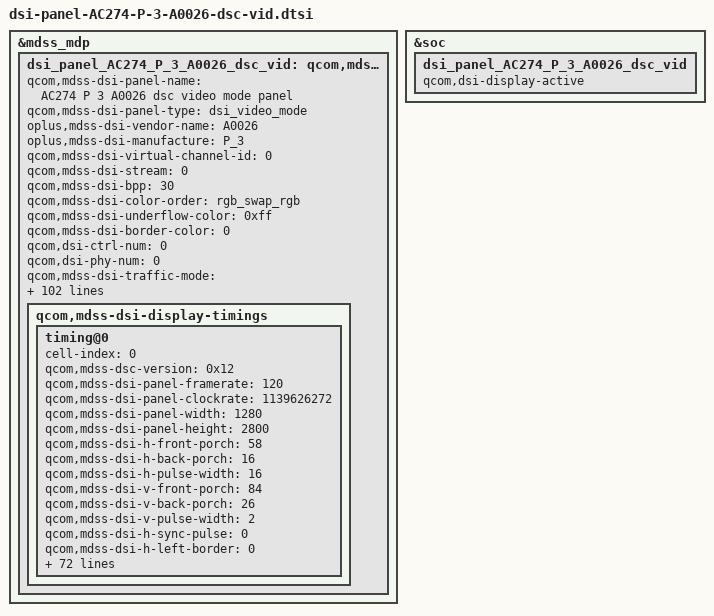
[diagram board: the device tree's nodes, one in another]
&mdss_mdp {
	dsi_panel_AC274_P_3_A0026_dsc_vid: qcom,mdss_dsi_panel_AC274_P_3_A0026_dsc_vid {
		qcom,mdss-dsi-panel-name = "AC274 P 3 A0026 dsc video mode panel";
		qcom,mdss-dsi-panel-type = "dsi_video_mode";
		oplus,mdss-dsi-vendor-name = "A0026";
		oplus,mdss-dsi-manufacture = "P_3";
		qcom,mdss-dsi-virtual-channel-id = <0>;
		qcom,mdss-dsi-stream = <0>;
		qcom,mdss-dsi-bpp = <30>;
		qcom,mdss-dsi-color-order = "rgb_swap_rgb";
		qcom,mdss-dsi-underflow-color = <0xff>;
		qcom,mdss-dsi-border-color = <0>;
		qcom,dsi-ctrl-num = <0>;
		qcom,dsi-phy-num = <0>;
		qcom,mdss-dsi-traffic-mode = "non_burst_sync_pulse";
		qcom,mdss-dsi-lane-map = "lane_map_0123";
		qcom,mdss-dsi-bllp-eof-power-mode;
		qcom,mdss-dsi-bllp-power-mode;
		qcom,mdss-dsi-lane-0-state;
		qcom,mdss-dsi-lane-1-state;
		qcom,mdss-dsi-lane-2-state;
		qcom,mdss-dsi-lane-3-state;
		qcom,mdss-dsi-dma-trigger = "trigger_sw";
		qcom,mdss-dsi-mdp-trigger = "none";
		qcom,mdss-dsi-reset-sequence = <1 10>, <0 10>, <1 25>;
		qcom,mdss-pan-physical-width-dimension = <72>;
		qcom,mdss-pan-physical-height-dimension = <157>;
		qcom,mdss-dsi-init-delay-us = <1000>;
		qcom,mdss-dsi-panel-jitter = <0x4 0x1>;
		/* disable cesta */
		qcom,mdss-disable-cesta-hw-sleep;
		//qcom,mdss-dsi-dma-schedule-line = <5>;
		qcom,mdss-dsi-dma-schedule-line-60 = <2600>;
		qcom,mdss-dsi-dma-schedule-line-90 = <600>;
		qcom,mdss-dsi-dma-schedule-line-120 = <30>;
		//qcom,mdss-bl-high2bit;
		//qcom,mdss-disable-cesta-hw-sleep;
		//qcom,mdss-dsi-panel-peak-brightness = <5400000>;
		/* HDR Setting */
		//update for [MPC15]PerformanceClassTest#testDisplayHdr pass
		qcom,mdss-dsi-panel-hdr-enabled;
		qcom,mdss-dsi-panel-hdr-color-primaries = <15635 16450 34000 16000 13250 34500 7500 3000>;
		qcom,mdss-dsi-panel-peak-brightness = <20000000>;
		qcom,mdss-dsi-panel-average-brightness = <2000000>;
		qcom,mdss-dsi-panel-blackness-level = <4000>;
		/*color*/
		oplus,color_vivid_status;
		//oplus,color_srgb_status;
		//oplus,color_softiris_status;
		//oplus,color_oplus_calibrate_status;
		//oplus,color_dual_brightness_status;
		//oplus,color_2nit_status;
		//oplus,color_loading_status;
		//oplus,color_nature_profession_status;
		//oplus,mdss-dsi-panel-type = <0>;
		//qcom,dynamic-mode-switch-enabled;
		qcom,dynamic-mode-switch-type = "dynamic-resolution-switch-immediate";
		qcom,mdss-dsi-display-timings {
			timing@0 {
				#include "dsi-panel-AC274-P-3-A0026-common-effect.dtsi"
				cell-index = <0>;
				//qcom,mdss-mdp-transfer-time-us = <6290>;
				//qcom,mdss-dsi-panel-jitter = <0x4 0x1>;
				qcom,mdss-dsc-version = <0x12>;
				//qcom,mdss-dsi-timing-default;
				qcom,mdss-dsi-panel-framerate = <120>;
				qcom,mdss-dsi-panel-clockrate = <1139626272>;
				qcom,mdss-dsi-panel-width = <1280>;
				qcom,mdss-dsi-panel-height = <2800>;

				qcom,mdss-dsi-h-front-porch = <58>;
				qcom,mdss-dsi-h-back-porch = <16>;
				qcom,mdss-dsi-h-pulse-width = <16>;
				qcom,mdss-dsi-v-front-porch = <84>;
				qcom,mdss-dsi-v-back-porch = <26>;
				qcom,mdss-dsi-v-pulse-width = <2>;
				qcom,mdss-dsi-h-sync-pulse = <0>;
				qcom,mdss-dsi-h-left-border = <0>;
				qcom,mdss-dsi-h-right-border = <0>;
				qcom,mdss-dsi-v-top-border = <0>;
				qcom,mdss-dsi-v-bottom-border = <0>;

				//oplus,ofp-need-to-sync-data-in-aod-unlocking;
				//oplus,ofp-aod-off-insert-black-frame = <1>;
				//oplus,ofp-aod-off-black-frame-total-time = <42>;
				//oplus,ofp-need-to-separate-backlight;
				//oplus,ofp-backlight-on-period = <1>;

				/* panel C1 PVT */
				qcom,mdss-dsi-on-command = [
					/* OSC2 = 138.9Mhz */
					39 00 00 40 00 00 06 F0 55 AA 52 08 01
					15 00 00 40 00 00 02 6F 03
					15 00 00 40 00 00 02 C4 62
					/* VGXP by pad cap */
					39 00 00 40 00 00 05 FF AA 55 A5 80
					15 00 00 40 00 00 02 6F 1F
					15 00 00 40 00 00 02 F4 0F
					15 00 00 40 00 00 02 6F 20
					39 00 00 40 00 00 02 F4 0F
					15 00 00 40 00 00 02 6F 08
					15 00 00 40 00 00 02 FC 01
					39 00 00 40 00 00 05 FF AA 55 A5 80
					15 00 00 40 00 00 02 6F 24
					15 00 00 40 00 00 02 F8 FF
					/* esd enhance*/
					39 00 00 40 00 00 06 F0 55 AA 52 08 00
					15 00 00 40 00 00 02 6F 0F
					15 00 00 40 00 00 02 D8 42
					39 00 00 40 00 00 06 F0 55 AA 52 08 00
					15 00 00 40 00 00 02 6F D4
					15 00 00 40 00 00 02 BA 20
					39 00 00 40 00 00 06 F0 55 AA 52 08 03
					15 00 00 40 00 00 02 C6 87
					/* For idle enter BIST */
					39 00 00 40 00 00 06 F0 55 AA 52 08 00
					15 00 00 40 00 00 02 C0 00
					39 00 00 40 00 00 06 F0 55 AA 52 08 01
					15 00 00 40 00 00 02 6F 0B
					39 00 00 40 00 00 02 D2 00
					39 00 00 40 00 00 05 FF AA 55 A5 84
					15 00 00 40 00 00 02 6F 10
					39 00 00 40 00 00 02 F8 02
					39 00 00 40 00 00 05 FF AA 55 A5 84
					15 00 00 40 00 00 02 F2 15
					/* LCTC Constraint for esd improve*/
					39 00 00 40 00 00 05 FF AA 55 A5 84
					15 00 00 40 00 00 02 6F A9
					15 00 00 40 00 00 02 F4 F3
					/* Resolution Setting */
					39 00 00 40 00 00 05 2A 00 00 04 FF
					39 00 00 40 00 00 05 2B 00 00 0A EF
					/* Vesa1.2 10bit 3.75 Dsc Setting */
					15 00 00 40 00 00 02 90 03
					15 00 00 40 00 00 02 6F 01
					39 00 00 40 00 00 02 90 43
					39 00 00 40 00 00 13 91 AB A8 00 28 D2 00 02 5C 04 06 00 08 02 AB 02 20 10 E0
					/* Dimming Off */
					15 00 00 40 00 00 02 53 20
					/* video mode ext_vfp,vbp setting */
					39 00 00 40 00 00 11 3B 00 1C 00 58 00 1C 00 54 00 1C 04 0C 00 1C 0B B4
					15 00 00 40 00 00 02 6F 10
					39 00 00 40 00 00 05 3B 00 1C 00 54
					/* DPC Temperature Setting */
					39 00 00 40 00 00 03 81 01 19
					/* FPR1 EN */
					15 00 00 40 00 00 02 88 01
					/* 120Hz sleep out */
					39 00 00 40 00 00 07 A9 01 00 2F 00 00 01
					/* TE on */
					15 00 00 40 00 00 02 35 00
					/* Setting loading effect x1.0 */
					39 00 00 40 00 00 03 5F 00 00
					/* Optimize the slight blue smear in low brightness */
					39 00 00 40 00 00 06 F0 55 AA 52 08 08
					39 00 00 40 00 00 05 E0 41 01 01 01
					15 00 00 40 00 00 02 6F 1C
					39 00 00 40 00 00 05 E1 01 07 0D 05
					15 00 00 40 00 00 02 6F 2A
					39 00 00 40 00 00 05 E1 01 0B 0D 04
					15 00 00 40 00 00 02 6F 38
					39 00 00 40 00 00 05 E1 02 0B 0A 08
					15 00 00 40 00 00 02 6F 46
					39 00 00 40 00 00 05 E1 02 09 08 05
					15 00 00 40 00 00 02 6F 54
					39 00 00 40 00 00 05 E1 01 07 09 04

					15 00 00 40 00 00 02 6F 1C
					39 00 00 40 00 00 05 E2 01 09 0D 05
					15 00 00 40 00 00 02 6F 2A
					39 00 00 40 00 00 05 E2 02 0D 0E 06
					15 00 00 40 00 00 02 6F 38
					39 00 00 40 00 00 05 E2 02 09 0A 07
					15 00 00 40 00 00 02 6F 46
					39 00 00 40 00 00 05 E2 02 09 09 07
					15 00 00 40 00 00 02 6F 54
					39 00 00 40 00 00 05 E2 02 07 0B 02
					/* swire pulse */
					39 00 00 40 00 00 06 F0 55 AA 52 08 00
					15 00 00 40 00 00 02 6F 03
					15 00 00 00 00 00 02 B5 D5
					/* Sleep out */
					/* FOD Coordinate location */
					39 00 00 40 00 00 06 F0 55 AA 52 08 00
					15 00 00 40 00 00 02 6F 07
					39 00 00 40 00 00 03 DF 02 1C
					15 00 00 40 00 00 02 6F 09
					39 00 00 40 00 00 03 DF 09 8C
					15 00 00 40 00 00 02 6F 0B
					39 00 00 40 00 00 03 DF 02 E6
					15 00 00 40 00 00 02 6F 0D
					39 00 00 40 00 00 03 DF 0A 56
					/* VDO Trim 139 */
					39 00 00 40 00 00 06 F0 55 AA 52 08 01
					15 00 00 40 00 00 02 6F 04
					15 00 00 40 00 00 02 C3 0A
					15 00 00 40 00 00 02 6F 09
					15 00 00 40 00 00 02 C3 0A

					15 00 00 40 00 00 02 EA C0
					15 00 00 40 00 00 02 6F 11
					15 00 00 40 00 00 02 EA C0
					15 00 00 40 00 00 02 6F 07
					39 00 00 40 00 00 06 EA 01 04 01 39 01
					15 00 00 40 00 00 02 6F 0C
					39 00 00 40 00 00 06 EA 3A 01 39 04 E2
					15 00 00 40 00 00 02 6F 18
					39 00 00 40 00 00 06 EA 01 4A 01 8E 01
					15 00 00 40 00 00 02 6F 1D
					39 00 00 40 00 00 06 EA 90 01 8E 06 37
					39 00 00 40 00 00 06 F0 55 AA 52 08 01
					15 00 00 40 00 00 02 6F 9B
					15 00 00 40 00 00 02 B9 80
					15 00 00 40 00 00 02 6F C3
					39 00 00 40 00 00 03 B9 01 80
					15 00 00 40 00 00 02 6F CB
					39 00 00 40 00 00 03 B9 01 80
					15 00 00 40 00 00 02 6F D3
					39 00 00 40 00 00 03 B9 01 80
					39 00 00 40 00 00 06 F0 55 AA 52 08 00
					39 00 00 40 00 00 05 FF AA 55 A5 80
					15 00 00 40 00 00 02 6F 47
					15 00 00 40 00 00 02 F2 21
					15 00 00 00 78 00 02 11 00
					15 00 00 00 14 00 02 29 00
					/*lhbm brightness -W255 Demora Gain -> 0*/
					39 00 00 40 00 00 06 F0 55 AA 52 08 04
					15 00 00 00 00 00 02 CB 06
				];

				/* panel C3 & T0 */
				qcom,mdss-dsi-optimize-on-command = [
					/* OSC2 = 138.9Mhz */
					39 00 00 40 00 00 06 F0 55 AA 52 08 01
					15 00 00 40 00 00 02 6F 03
					15 00 00 40 00 00 02 C4 62
					/* VGXP by pad cap */
					39 00 00 40 00 00 05 FF AA 55 A5 80
					15 00 00 40 00 00 02 6F 1F
					15 00 00 40 00 00 02 F4 0F
					15 00 00 40 00 00 02 6F 20
					39 00 00 40 00 00 02 F4 0F
					15 00 00 40 00 00 02 6F 08
					15 00 00 40 00 00 02 FC 01
					39 00 00 40 00 00 05 FF AA 55 A5 80
					15 00 00 40 00 00 02 6F 24
					15 00 00 40 00 00 02 F8 FF
					/* esd enhance*/
					39 00 00 40 00 00 06 F0 55 AA 52 08 00
					15 00 00 40 00 00 02 6F 0F
					15 00 00 40 00 00 02 D8 42
					39 00 00 40 00 00 06 F0 55 AA 52 08 00
					15 00 00 40 00 00 02 6F D4
					15 00 00 40 00 00 02 BA 20
					39 00 00 40 00 00 06 F0 55 AA 52 08 03
					15 00 00 40 00 00 02 C6 87
					/* For idle enter BIST */
					39 00 00 40 00 00 06 F0 55 AA 52 08 00
					15 00 00 40 00 00 02 C0 00
					39 00 00 40 00 00 06 F0 55 AA 52 08 01
					15 00 00 40 00 00 02 6F 0B
					39 00 00 40 00 00 02 D2 00
					39 00 00 40 00 00 05 FF AA 55 A5 84
					15 00 00 40 00 00 02 6F 10
					39 00 00 40 00 00 02 F8 02
					39 00 00 40 00 00 05 FF AA 55 A5 84
					15 00 00 40 00 00 02 F2 15
					/* LCTC Constraint For ESD Improve */
					39 00 00 40 00 00 05 FF AA 55 A5 84
					15 00 00 40 00 00 02 6F A9
					15 00 00 40 00 00 02 F4 F3
					/* CSC Setting */
					15 00 00 40 00 00 02 6F 14
					39 00 00 40 00 00 0A B0 F5 55 55 56 AA AA AA AA A8
					/* Resolution Setting */
					39 00 00 40 00 00 05 2A 00 00 04 FF
					39 00 00 40 00 00 05 2B 00 00 0A EF
					/* Vesa1.2 10bit 3.75 Dsc Setting */
					15 00 00 40 00 00 02 90 03
					15 00 00 40 00 00 02 6F 01
					39 00 00 40 00 00 02 90 43
					39 00 00 40 00 00 13 91 AB A8 00 28 D2 00 02 5C 04 06 00 08 02 AB 02 20 10 E0
					/* Dimming Off */
					15 00 00 40 00 00 02 53 20
					/* video mode ext_vfp,vbp setting */
					39 00 00 40 00 00 11 3B 00 1C 00 58 00 1C 00 54 00 1C 04 0C 00 1C 0B B4
					15 00 00 40 00 00 02 6F 10
					39 00 00 40 00 00 05 3B 00 1C 00 54
					/* DPC Temperature Setting */
					39 00 00 40 00 00 03 81 01 19
					/* FPR1 EN */
					15 00 00 40 00 00 02 88 01
					/* 120Hz sleep out */
					39 00 00 40 00 00 07 A9 01 00 2F 00 00 01
					/* TE on */
					15 00 00 40 00 00 02 35 00
					/* Setting loading effect x1.0 */
					39 00 00 40 00 00 03 5F 00 00
					/* Optimize the slight blue smear in low brightness */
					39 00 00 40 00 00 06 F0 55 AA 52 08 08
					39 00 00 40 00 00 05 E0 41 01 01 01
					15 00 00 40 00 00 02 6F 1C
					39 00 00 40 00 00 05 E1 01 07 0D 05
					15 00 00 40 00 00 02 6F 2A
					39 00 00 40 00 00 05 E1 01 0B 0D 04
					15 00 00 40 00 00 02 6F 38
					39 00 00 40 00 00 05 E1 02 0B 0A 08
					15 00 00 40 00 00 02 6F 46
					39 00 00 40 00 00 05 E1 02 09 08 05
					15 00 00 40 00 00 02 6F 54
					39 00 00 40 00 00 05 E1 01 07 09 04

					15 00 00 40 00 00 02 6F 1C
					39 00 00 40 00 00 05 E2 01 09 0D 05
					15 00 00 40 00 00 02 6F 2A
					39 00 00 40 00 00 05 E2 02 0D 0E 06
					15 00 00 40 00 00 02 6F 38
					39 00 00 40 00 00 05 E2 02 09 0A 07
					15 00 00 40 00 00 02 6F 46
					39 00 00 40 00 00 05 E2 02 09 09 07
					15 00 00 40 00 00 02 6F 54
					39 00 00 40 00 00 05 E2 02 07 0B 02
					/* swire pulse */
					39 00 00 40 00 00 06 F0 55 AA 52 08 00
					15 00 00 40 00 00 02 6F 03
					15 00 00 00 00 00 02 B5 D5
					/* Sleep out */
					/* FOD Coordinate location */
					39 00 00 40 00 00 06 F0 55 AA 52 08 00
					15 00 00 40 00 00 02 6F 07
					39 00 00 40 00 00 03 DF 02 1C
					15 00 00 40 00 00 02 6F 09
					39 00 00 40 00 00 03 DF 09 8C
					15 00 00 40 00 00 02 6F 0B
					39 00 00 40 00 00 03 DF 02 E6
					15 00 00 40 00 00 02 6F 0D
					39 00 00 40 00 00 03 DF 0A 56
					/* VDO Trim 139 */
					39 00 00 40 00 00 06 F0 55 AA 52 08 01
					15 00 00 40 00 00 02 6F 04
					15 00 00 40 00 00 02 C3 0A
					15 00 00 40 00 00 02 6F 09
					15 00 00 40 00 00 02 C3 0A

					15 00 00 40 00 00 02 EA C0
					15 00 00 40 00 00 02 6F 11
					15 00 00 40 00 00 02 EA C0
					15 00 00 40 00 00 02 6F 07
					39 00 00 40 00 00 06 EA 01 04 01 39 01
					15 00 00 40 00 00 02 6F 0C
					39 00 00 40 00 00 06 EA 3A 01 39 04 E2
					15 00 00 40 00 00 02 6F 18
					39 00 00 40 00 00 06 EA 01 4A 01 8E 01
					15 00 00 40 00 00 02 6F 1D
					39 00 00 40 00 00 06 EA 90 01 8E 06 37
					39 00 00 40 00 00 06 F0 55 AA 52 08 01
					15 00 00 40 00 00 02 6F 9B
					15 00 00 40 00 00 02 B9 80
					15 00 00 40 00 00 02 6F C3
					39 00 00 40 00 00 03 B9 01 80
					15 00 00 40 00 00 02 6F CB
					39 00 00 40 00 00 03 B9 01 80
					15 00 00 40 00 00 02 6F D3
					39 00 00 40 00 00 03 B9 01 80
					39 00 00 40 00 00 06 F0 55 AA 52 08 00
					39 00 00 40 00 00 05 FF AA 55 A5 80
					15 00 00 40 00 00 02 6F 47
					15 00 00 40 00 00 02 F2 21
					15 00 00 00 78 00 02 11 00
					15 00 00 00 14 00 02 29 00
					/*lhbm brightness -W255 Demora Gain -> 0*/
					39 00 00 40 00 00 06 F0 55 AA 52 08 04
					15 00 00 00 00 00 02 CB 06
				];

				/* panel C2 */
				qcom,mdss-dsi-optimize-vice-on-command = [
					/* OSC2 = 138.9Mhz */
					39 00 00 40 00 00 06 F0 55 AA 52 08 01
					15 00 00 40 00 00 02 6F 03
					15 00 00 40 00 00 02 C4 62
					/* VGXP by pad cap */
					39 00 00 40 00 00 05 FF AA 55 A5 80
					15 00 00 40 00 00 02 6F 1F
					15 00 00 40 00 00 02 F4 0F
					15 00 00 40 00 00 02 6F 20
					39 00 00 40 00 00 02 F4 0F
					15 00 00 40 00 00 02 6F 08
					15 00 00 40 00 00 02 FC 01
					39 00 00 40 00 00 05 FF AA 55 A5 80
					15 00 00 40 00 00 02 6F 24
					15 00 00 40 00 00 02 F8 FF
					/* esd enhance*/
					39 00 00 40 00 00 06 F0 55 AA 52 08 00
					15 00 00 40 00 00 02 6F 0F
					15 00 00 40 00 00 02 D8 42
					39 00 00 40 00 00 06 F0 55 AA 52 08 00
					15 00 00 40 00 00 02 6F D4
					15 00 00 40 00 00 02 BA 20
					39 00 00 40 00 00 06 F0 55 AA 52 08 03
					15 00 00 40 00 00 02 C6 87
					/* For idle enter BIST */
					39 00 00 40 00 00 06 F0 55 AA 52 08 00
					15 00 00 40 00 00 02 C0 00
					39 00 00 40 00 00 06 F0 55 AA 52 08 01
					15 00 00 40 00 00 02 6F 0B
					39 00 00 40 00 00 02 D2 00
					39 00 00 40 00 00 05 FF AA 55 A5 84
					15 00 00 40 00 00 02 6F 10
					39 00 00 40 00 00 02 F8 02
					39 00 00 40 00 00 05 FF AA 55 A5 84
					15 00 00 40 00 00 02 F2 15
					/* LCTC Constraint For ESD Improve */
					39 00 00 40 00 00 05 FF AA 55 A5 84
					15 00 00 40 00 00 02 6F A9
					15 00 00 40 00 00 02 F4 F3
					/* Resolution Setting */
					39 00 00 40 00 00 05 2A 00 00 04 FF
					39 00 00 40 00 00 05 2B 00 00 0A EF
					/* Vesa1.2 10bit 3.75 Dsc Setting */
					15 00 00 40 00 00 02 90 03
					15 00 00 40 00 00 02 6F 01
					39 00 00 40 00 00 02 90 43
					39 00 00 40 00 00 13 91 AB A8 00 28 D2 00 02 5C 04 06 00 08 02 AB 02 20 10 E0
					/* Dimming Off */
					15 00 00 40 00 00 02 53 20
					/* video mode ext_vfp,vbp setting */
					39 00 00 40 00 00 11 3B 00 1C 00 58 00 1C 00 54 00 1C 04 0C 00 1C 0B B4
					15 00 00 40 00 00 02 6F 10
					39 00 00 40 00 00 05 3B 00 1C 00 54
					/* DPC Temperature Setting */
					39 00 00 40 00 00 03 81 01 19
					/* FPR1 EN */
					15 00 00 40 00 00 02 88 01
					/* 120Hz sleep out */
					39 00 00 40 00 00 07 A9 01 00 2F 00 00 01
					/* TE on */
					15 00 00 40 00 00 02 35 00
					/* Setting loading effect x1.0 */
					39 00 00 40 00 00 03 5F 00 00
					/* Optimize the slight blue smear in low brightness */
					39 00 00 40 00 00 06 F0 55 AA 52 08 08
					39 00 00 40 00 00 05 E0 41 01 01 01
					15 00 00 40 00 00 02 6F 1C
					39 00 00 40 00 00 05 E1 01 07 0D 05
					15 00 00 40 00 00 02 6F 2A
					39 00 00 40 00 00 05 E1 01 0B 0D 04
					15 00 00 40 00 00 02 6F 38
					39 00 00 40 00 00 05 E1 02 0B 0A 08
					15 00 00 40 00 00 02 6F 46
					39 00 00 40 00 00 05 E1 02 09 08 05
					15 00 00 40 00 00 02 6F 54
					39 00 00 40 00 00 05 E1 01 07 09 04

					15 00 00 40 00 00 02 6F 1C
					39 00 00 40 00 00 05 E2 01 09 0D 05
					15 00 00 40 00 00 02 6F 2A
					39 00 00 40 00 00 05 E2 02 0D 0E 06
					15 00 00 40 00 00 02 6F 38
					39 00 00 40 00 00 05 E2 02 09 0A 07
					15 00 00 40 00 00 02 6F 46
					39 00 00 40 00 00 05 E2 02 09 09 07
					15 00 00 40 00 00 02 6F 54
					39 00 00 40 00 00 05 E2 02 07 0B 02
					/* swire pulse */
					39 00 00 40 00 00 06 F0 55 AA 52 08 00
					15 00 00 40 00 00 02 6F 03
					15 00 00 00 00 00 02 B5 D5
					/* Sleep out */
					/* FOD Coordinate location */
					39 00 00 40 00 00 06 F0 55 AA 52 08 00
					15 00 00 40 00 00 02 6F 07
					39 00 00 40 00 00 03 DF 02 1C
					15 00 00 40 00 00 02 6F 09
					39 00 00 40 00 00 03 DF 09 8C
					15 00 00 40 00 00 02 6F 0B
					39 00 00 40 00 00 03 DF 02 E6
					15 00 00 40 00 00 02 6F 0D
					39 00 00 40 00 00 03 DF 0A 56
					/* VDO Trim 139 */
					39 00 00 40 00 00 06 F0 55 AA 52 08 01
					15 00 00 40 00 00 02 6F 04
					15 00 00 40 00 00 02 C3 0A
					15 00 00 40 00 00 02 6F 09
					15 00 00 40 00 00 02 C3 0A

					15 00 00 40 00 00 02 EA C0
					15 00 00 40 00 00 02 6F 11
					15 00 00 40 00 00 02 EA C0
					15 00 00 40 00 00 02 6F 07
					39 00 00 40 00 00 06 EA 01 04 01 39 01
					15 00 00 40 00 00 02 6F 0C
					39 00 00 40 00 00 06 EA 3A 01 39 04 E2
					15 00 00 40 00 00 02 6F 18
					39 00 00 40 00 00 06 EA 01 4A 01 8E 01
					15 00 00 40 00 00 02 6F 1D
					39 00 00 40 00 00 06 EA 90 01 8E 06 37
					39 00 00 40 00 00 06 F0 55 AA 52 08 01
					15 00 00 40 00 00 02 6F 9B
					15 00 00 40 00 00 02 B9 80
					15 00 00 40 00 00 02 6F C3
					39 00 00 40 00 00 03 B9 01 80
					15 00 00 40 00 00 02 6F CB
					39 00 00 40 00 00 03 B9 01 80
					15 00 00 40 00 00 02 6F D3
					39 00 00 40 00 00 03 B9 01 80
					39 00 00 40 00 00 06 F0 55 AA 52 08 00
					39 00 00 40 00 00 05 FF AA 55 A5 80
					15 00 00 40 00 00 02 6F 47
					15 00 00 40 00 00 02 F2 21
					15 00 00 00 78 00 02 11 00
					15 00 00 00 14 00 02 29 00
					/*lhbm brightness -W255 Demora Gain -> 0*/
					39 00 00 40 00 00 06 F0 55 AA 52 08 04
					15 00 00 00 00 00 02 CB 06
				];

				qcom,mdss-dsi-off-command=[
					15 00 00 00 14 00 02 28 00
					15 00 00 00 78 00 02 10 00
				];

				qcom,mdss-dsi-lp1-command = [
					15 00 00 60 00 00 02 6F 04
					39 00 00 60 00 00 03 51 0F FE
					05 00 00 20 00 00 01 39
				];
				qcom,mdss-dsi-nolp-command = [
					05 00 00 60 00 00 01 38
					39 00 00 20 00 00 03 51 00 00
				];

				qcom,mdss-dsi-aod-high-mode-command = [
					/* AOD High Mode 50nit */
					15 00 00 60 00 00 02 6F 04
					39 00 00 20 00 00 03 51 0F FE
				];
				qcom,mdss-dsi-aod-low-mode-command = [
					/* AOD Low Mode 10nit */
					15 00 00 60 00 00 02 6F 04
					39 00 00 00 00 00 03 51 0D BB
				];
				qcom,mdss-dsi-lhbm-pressed-icon-on-command = [
					39 00 00 50 00 00 07 A9 01 00 2F 00 00 01
					39 00 00 50 00 00 35 A9 02 08 B1 00 00 03 02 08 C1 00 07 8E 90 EE 90 90 EE 90 90 02 08 C1 08 0A EE D0 D0 02 01 B9 1D 1D 08 02 09 B0 00 00 11 01 00 8B 00 01 10 01 01 00 87 00 00 25
					39 00 00 10 00 00 2E A9 01 00 A2 00 27 03 02 08 C1 00 07 8E FF EE FF FF EE FF FF 02 08 C1 08 0A EE FF FF 00 00 00 00 00 02 01 B9 1D 1D 08 00 00 00 00 00 00 00
				];
				qcom,mdss-dsi-lhbm-pressed-icon-off-command = [
					39 00 00 50 00 00 35 A9 02 08 B1 00 00 02 02 08 C1 00 07 8F 50 FF 50 50 FF 50 50 02 08 C1 08 0A FF 50 50 02 01 B9 1D 1D 08 02 09 B0 00 00 01 01 00 8B 00 01 00 00 01 00 87 00 00 00
					39 00 00 10 00 00 2E A9 01 00 A2 00 27 03 02 08 C1 00 07 8E FF EE FF FF EE FF FF 02 08 C1 08 0A EE FF FF 00 00 00 00 00 02 01 B9 1D 1D 08 00 00 00 00 00 00 00
				];

				qcom,dsi-panel-date-switch-command = [
					/*read panel info switch page 01*/
					39 00 00 00 00 00 06 F0 55 AA 52 08 01
				];

				qcom,mdss-dsi-default-switch-page-command = [
					39 00 00 00 00 00 06 F0 55 AA 52 08 00
				];

				qcom,mdss-dsi-vid-120hz-switch-command = [
					39 00 00 10 00 00 07 A9 01 00 2F 00 00 01
				];

				qcom,mdss-dsi-vid-90hz-switch-command = [
					39 00 00 10 00 00 07 A9 01 00 2F 00 00 02
				];

				qcom,mdss-dsi-vid-60hz-switch-command = [
					39 00 00 10 00 00 07 A9 01 00 2F 00 00 03
				];

				qcom,dsi-panel-date-switch-command-state = "dsi_lp_mode";
				qcom,mdss-dsi-default-switch-page-command-state = "dsi_lp_mode";
				qcom,mdss-dsi-vid-120hz-switch-command-state = "dsi_lp_mode";
				qcom,mdss-dsi-vid-90hz-switch-command-state = "dsi_lp_mode";
				qcom,mdss-dsi-vid-60hz-switch-command-state = "dsi_lp_mode";
				qcom,mdss-dsi-on-command-state = "dsi_lp_mode";
				qcom,mdss-dsi-optimize-on-command-state = "dsi_lp_mode";
				qcom,mdss-dsi-optimize-vice-on-command-state = "dsi_lp_mode";
				qcom,mdss-dsi-off-command-state = "dsi_lp_mode";
				qcom,mdss-dsi-lp1-command-state = "dsi_hs_mode";
				qcom,mdss-dsi-nolp-command-state = "dsi_hs_mode";
				qcom,mdss-dsi-aod-high-mode-command-state = "dsi_hs_mode";
				qcom,mdss-dsi-aod-low-mode-command-state = "dsi_hs_mode";
				qcom,mdss-dsi-lhbm-pressed-icon-on-command-state = "dsi_hs_mode";
				qcom,mdss-dsi-lhbm-pressed-icon-off-command-state = "dsi_hs_mode";
				qcom,lm-split = <640 640>;
				qcom,compression-mode = "dsc";
				qcom,mdss-dsc-encoders = <2>;
				qcom,mdss-dsc-slice-height = <40>;
				qcom,mdss-dsc-slice-width = <640>;
				qcom,mdss-dsc-slice-per-pkt = <2>;
				qcom,mdss-dsc-bit-per-component = <10>;
				qcom,mdss-dsc-bit-per-pixel = <8>;
				qcom,mdss-dsc-block-prediction-enable;
			};
		};
	};
};

&soc {
	dsi_panel_AC274_P_3_A0026_dsc_vid {
		qcom,dsi-display-active;
	};
};

&dsi_panel_AC274_P_3_A0026_dsc_vid {
	qcom,panel-supply-entries = <&oplus_dsi_panel_custom_pwr_supply>;
	qcom,platform-te-gpio = <&tlmm 77 0>;
	qcom,platform-reset-gpio = <&tlmm 14 0>;
	oplus,panel-gpio1 = <&tlmm 76 0>;

	oplus,panel-reset-position = <0x02>;
	oplus,panel-power-on-sequence = "1", "vddio", "3", "gpio1", "3", "vci", "10";
	oplus,panel-power-off-sequence = "1", "vci", "3", "gpio1", "3", "vddio", "1";

	//enable mipi strength
	//oplus,enhance_mipi_strength;

	/* BRIGHTNESS CONFIG */
	qcom,mdss-dsi-bl-pmic-control-type = "bl_ctrl_dcs";
	qcom,bl-update-flag = "delay_until_first_frame";
	qcom,mdss-dsi-bl-inverted-dbv;
	qcom,mdss-dsi-bl-min-level = <1>;
	qcom,mdss-dsi-bl-max-level = <4094>;
	qcom,mdss-brightness-max-level = <4094>;
	oplus,dsi-bl-normal-max-level = <3001>;
	oplus,dsi-brightness-normal-max-level = <3001>;
	oplus,dsi-dc-backlight-threshold = <1088>;
	oplus,dsi-brightness-default-level = <1638>;
	oplus,panel_backlight_check_disable;

	/* ofp config */
	oplus,ofp-fp-type = <0xA10>;

	/* aod brightness config*/
	oplus,video-mode-aod-brightness-change-enable;
	oplus,video-mode-aod-brightness-value-count= [02];
	oplus,video-mode-aod-high-brightness-value = [0F FE];
	oplus,video-mode-aod-low-brightness-value = [0D BB];

	/* esd config */
	qcom,esd-check-enabled;
	qcom,mdss-dsi-panel-status-check-mode = "reg_read";
	qcom,mdss-dsi-panel-status-command = [
		06 00 00 00 00 00 01 0A
		06 00 00 00 00 00 01 AB
		06 00 00 00 00 00 01 0D
	];
	qcom,mdss-dsi-panel-status-command-state = "dsi_lp_mode";
	qcom,mdss-dsi-panel-status-value = <
		0x9C 0x00 0x00 0x00
	>;
	qcom,mdss-dsi-panel-status-read-length = <1 2 1>;
	oplus,mdss-dsi-panel-status-match-modes = <0x00000000>;

	/* vid-timming-switch */
	oplus,dsi_vid_timming_switch_post_enable;
	/* fps-switch */
	qcom,mdss-dsi-pan-enable-dynamic-fps;
	qcom,mdss-dsi-pan-fps-update = "dfps_immediate_porch_mode_both_hv_porch";
	qcom,dsi-supported-dfps-list = <120    90    60    30>;
	qcom,dsi-dfps-hfp-list       = <58     58    58    1354>;
	qcom,dsi-dfps-hbp-list       = <16     16    16    16>;
	qcom,dsi-dfps-hpw-list       = <16     16    16    16>;
	qcom,dsi-dfps-vfp-list       = <84     1036  2996  84>;
	qcom,dsi-dfps-vbp-list       = <26     26    26    26>;
	qcom,dsi-dfps-vpw-list       = <2      2     2     2>;

	/* ignore some fps swicth factory test */
	oplus,factory-ignore-mode = <1 5>;

	/* OPLUS FEATURES CONFIG */
	oplus,dsi-serial-number-enabled;
	oplus,dsi-serial-number-switch-page;
	oplus,dsi-serial-number-index= <0>;
	oplus,dsi-serial-number-reg= <0xD7>;
	oplus,dsi-serial-number-read-count= <7>;
	qcom,ulps-enabled;
	qcom,dsi-select-clocks = "pll_byte_clk0", "pll_dsi_clk0";

	//oplus,vreg_ctrl_flag;

	//qcom,dsi-dyn-clk-enable;

	/* MIPI ERR check config */
	/*  BIT(0): enable/disable check
	** BIT(1): enable/disable page switch
	*/
	oplus,mipi-err-check-config = <0x01>; // 0b0000'0001
	oplus,mipi-err-check-reg = [
		AB
	];
	oplus,mipi-err-check-value = [
		00 00
	];
	oplus,mipi-err-check-count = [
		02
	];
	/* 32-bit binary flag
	** Bit value identified how to match the return value of each register.
	** The value 0(default) means equal, and the value 1 means not equal.
	*/
	oplus,mipi-err-check-match-modes = <0x00000000>;

	qcom,mdss-dsi-display-timings {
		timing@0 {
			qcom,mdss-dsi-panel-phy-timings = [00 25 0A 0A 1B 18 0A 0A 0A 02 04 00 1F 0F];
			qcom,display-topology = <1 1 1>,<2 2 1>;
			qcom,default-topology-index = <1>;
		};
	};
};

&dsi_panel_AC274_P_3_A0026_dsc_vid {
	qcom,panel_voltage_vddi_name = "vddio";
	qcom,panel_voltage_vddi = <1 1750000 1850000 1950000>;
	qcom,panel_voltage_vddr_name = "vci";
	qcom,panel_voltage_vddr = <1 3000000 3200000 3300000>;
};

